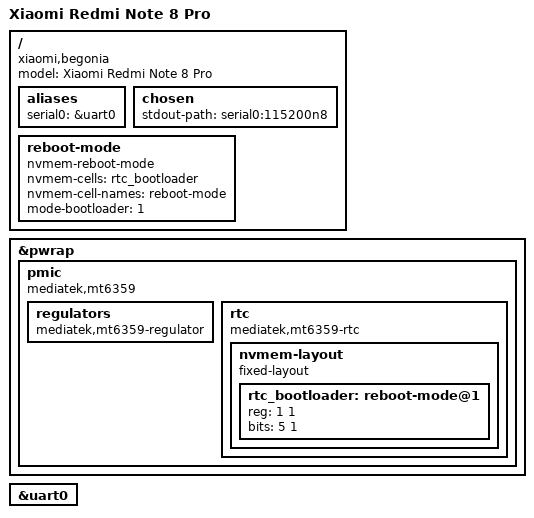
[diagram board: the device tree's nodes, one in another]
// SPDX-License-Identifier: (GPL-2.0 OR MIT)

/dts-v1/;
#include "mt6785.dtsi"

/ {
	model = "Xiaomi Redmi Note 8 Pro";
	compatible = "xiaomi,begonia", "mediatek,mt6785";

	aliases {
		serial0 = &uart0;
	};

	chosen {
		stdout-path = "serial0:115200n8";
	};

	reboot-mode {
		compatible = "nvmem-reboot-mode";
		nvmem-cells = <&rtc_bootloader>;
		nvmem-cell-names = "reboot-mode";
		mode-bootloader = <1>;
	};
};

&pwrap {
	pmic {
		compatible = "mediatek,mt6359";

		regulators {
			compatible = "mediatek,mt6359-regulator";
		};

		rtc {
			compatible = "mediatek,mt6359-rtc", "mediatek,mt6358-rtc";

			nvmem-layout {
				compatible = "fixed-layout";
				#address-cells = <1>;
				#size-cells = <1>;

				rtc_bootloader: reboot-mode@1 {
					reg = <1 1>;
					bits = <5 1>;
				};
			};
		};
	};
};

&uart0 {
	status = "okay";
};
